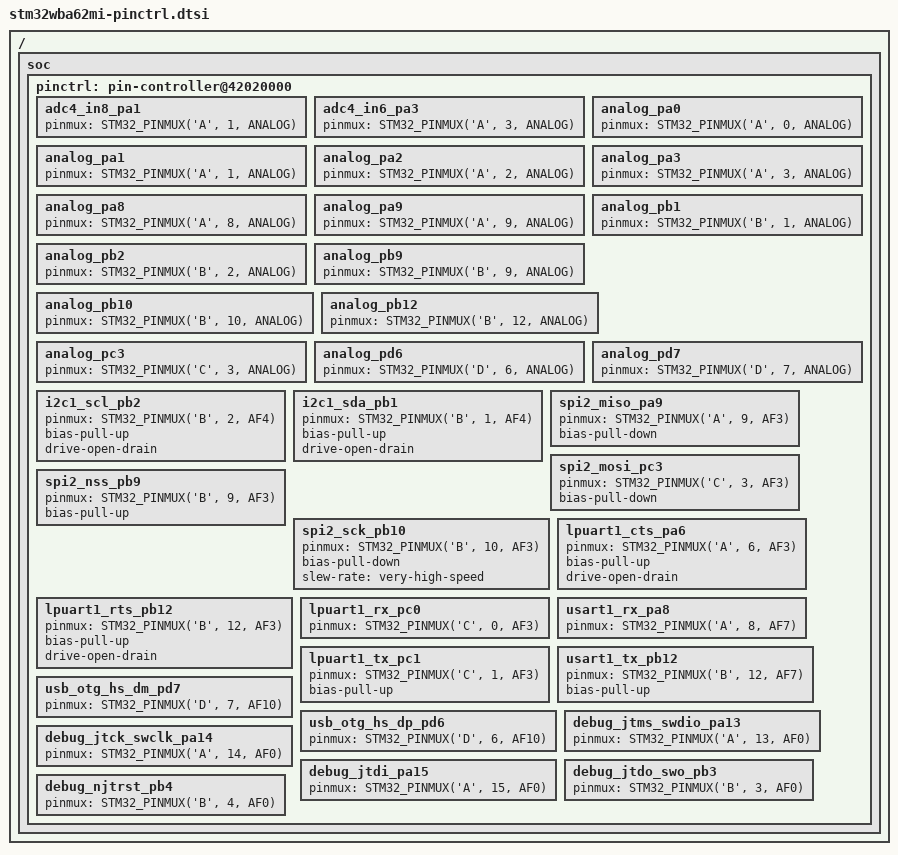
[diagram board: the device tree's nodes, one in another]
/*
 * NOTE: Autogenerated file using genpinctrl.py
 *
 * SPDX-License-Identifier: Apache-2.0
 */

#include <zephyr/dt-bindings/pinctrl/stm32-pinctrl.h>

/ {
	soc {
		pinctrl: pin-controller@42020000 {

			/* ADC_IN / ADC_INN / ADC_INP */

			/omit-if-no-ref/ adc4_in8_pa1: adc4_in8_pa1 {
				pinmux = <STM32_PINMUX('A', 1, ANALOG)>;
			};

			/omit-if-no-ref/ adc4_in6_pa3: adc4_in6_pa3 {
				pinmux = <STM32_PINMUX('A', 3, ANALOG)>;
			};

			/* Analog */

			/omit-if-no-ref/ analog_pa0: analog_pa0 {
				pinmux = <STM32_PINMUX('A', 0, ANALOG)>;
			};

			/omit-if-no-ref/ analog_pa1: analog_pa1 {
				pinmux = <STM32_PINMUX('A', 1, ANALOG)>;
			};

			/omit-if-no-ref/ analog_pa2: analog_pa2 {
				pinmux = <STM32_PINMUX('A', 2, ANALOG)>;
			};

			/omit-if-no-ref/ analog_pa3: analog_pa3 {
				pinmux = <STM32_PINMUX('A', 3, ANALOG)>;
			};

			/omit-if-no-ref/ analog_pa8: analog_pa8 {
				pinmux = <STM32_PINMUX('A', 8, ANALOG)>;
			};

			/omit-if-no-ref/ analog_pa9: analog_pa9 {
				pinmux = <STM32_PINMUX('A', 9, ANALOG)>;
			};

			/omit-if-no-ref/ analog_pb1: analog_pb1 {
				pinmux = <STM32_PINMUX('B', 1, ANALOG)>;
			};

			/omit-if-no-ref/ analog_pb2: analog_pb2 {
				pinmux = <STM32_PINMUX('B', 2, ANALOG)>;
			};

			/omit-if-no-ref/ analog_pb9: analog_pb9 {
				pinmux = <STM32_PINMUX('B', 9, ANALOG)>;
			};

			/omit-if-no-ref/ analog_pb10: analog_pb10 {
				pinmux = <STM32_PINMUX('B', 10, ANALOG)>;
			};

			/omit-if-no-ref/ analog_pb12: analog_pb12 {
				pinmux = <STM32_PINMUX('B', 12, ANALOG)>;
			};

			/omit-if-no-ref/ analog_pc3: analog_pc3 {
				pinmux = <STM32_PINMUX('C', 3, ANALOG)>;
			};

			/omit-if-no-ref/ analog_pd6: analog_pd6 {
				pinmux = <STM32_PINMUX('D', 6, ANALOG)>;
			};

			/omit-if-no-ref/ analog_pd7: analog_pd7 {
				pinmux = <STM32_PINMUX('D', 7, ANALOG)>;
			};

			/* I2C_SCL */

			/omit-if-no-ref/ i2c1_scl_pb2: i2c1_scl_pb2 {
				pinmux = <STM32_PINMUX('B', 2, AF4)>;
				bias-pull-up;
				drive-open-drain;
			};

			/* I2C_SDA */

			/omit-if-no-ref/ i2c1_sda_pb1: i2c1_sda_pb1 {
				pinmux = <STM32_PINMUX('B', 1, AF4)>;
				bias-pull-up;
				drive-open-drain;
			};

			/* SPI_MISO */

			/omit-if-no-ref/ spi2_miso_pa9: spi2_miso_pa9 {
				pinmux = <STM32_PINMUX('A', 9, AF3)>;
				bias-pull-down;
			};

			/* SPI_MOSI */

			/omit-if-no-ref/ spi2_mosi_pc3: spi2_mosi_pc3 {
				pinmux = <STM32_PINMUX('C', 3, AF3)>;
				bias-pull-down;
			};

			/* SPI_NSS */

			/omit-if-no-ref/ spi2_nss_pb9: spi2_nss_pb9 {
				pinmux = <STM32_PINMUX('B', 9, AF3)>;
				bias-pull-up;
			};

			/* SPI_SCK */

			/omit-if-no-ref/ spi2_sck_pb10: spi2_sck_pb10 {
				pinmux = <STM32_PINMUX('B', 10, AF3)>;
				bias-pull-down;
				slew-rate = "very-high-speed";
			};

			/* UART_CTS / USART_CTS / LPUART_CTS */

			/omit-if-no-ref/ lpuart1_cts_pa6: lpuart1_cts_pa6 {
				pinmux = <STM32_PINMUX('A', 6, AF3)>;
				bias-pull-up;
				drive-open-drain;
			};

			/* UART_RTS / USART_RTS / LPUART_RTS */

			/omit-if-no-ref/ lpuart1_rts_pb12: lpuart1_rts_pb12 {
				pinmux = <STM32_PINMUX('B', 12, AF3)>;
				bias-pull-up;
				drive-open-drain;
			};

			/* UART_RX / USART_RX / LPUART_RX */

			/omit-if-no-ref/ lpuart1_rx_pc0: lpuart1_rx_pc0 {
				pinmux = <STM32_PINMUX('C', 0, AF3)>;
			};

			/omit-if-no-ref/ usart1_rx_pa8: usart1_rx_pa8 {
				pinmux = <STM32_PINMUX('A', 8, AF7)>;
			};

			/* UART_TX / USART_TX / LPUART_TX */

			/omit-if-no-ref/ lpuart1_tx_pc1: lpuart1_tx_pc1 {
				pinmux = <STM32_PINMUX('C', 1, AF3)>;
				bias-pull-up;
			};

			/omit-if-no-ref/ usart1_tx_pb12: usart1_tx_pb12 {
				pinmux = <STM32_PINMUX('B', 12, AF7)>;
				bias-pull-up;
			};

			/* USB_OTG_HS */

			/omit-if-no-ref/ usb_otg_hs_dm_pd7: usb_otg_hs_dm_pd7 {
				pinmux = <STM32_PINMUX('D', 7, AF10)>;
			};

			/omit-if-no-ref/ usb_otg_hs_dp_pd6: usb_otg_hs_dp_pd6 {
				pinmux = <STM32_PINMUX('D', 6, AF10)>;
			};

			/* DEBUG */

			/omit-if-no-ref/ debug_jtms_swdio_pa13: debug_jtms_swdio_pa13 {
				pinmux = <STM32_PINMUX('A', 13, AF0)>;
			};

			/omit-if-no-ref/ debug_jtck_swclk_pa14: debug_jtck_swclk_pa14 {
				pinmux = <STM32_PINMUX('A', 14, AF0)>;
			};

			/omit-if-no-ref/ debug_jtdi_pa15: debug_jtdi_pa15 {
				pinmux = <STM32_PINMUX('A', 15, AF0)>;
			};

			/omit-if-no-ref/ debug_jtdo_swo_pb3: debug_jtdo_swo_pb3 {
				pinmux = <STM32_PINMUX('B', 3, AF0)>;
			};

			/omit-if-no-ref/ debug_njtrst_pb4: debug_njtrst_pb4 {
				pinmux = <STM32_PINMUX('B', 4, AF0)>;
			};

		};
	};
};
